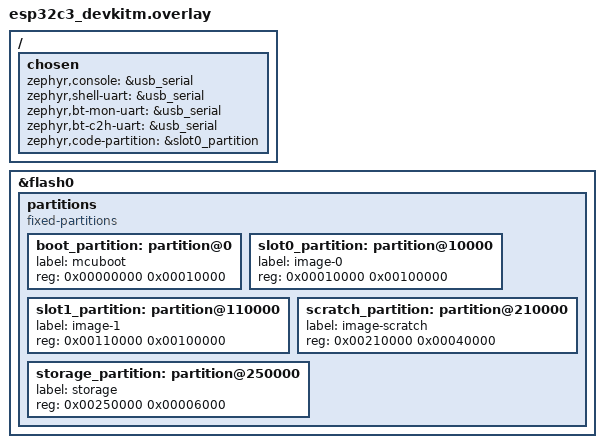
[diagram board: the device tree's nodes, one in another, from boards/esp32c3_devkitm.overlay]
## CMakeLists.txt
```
cmake_minimum_required(VERSION 3.20.0)

find_package(Zephyr REQUIRED HINTS $ENV{ZEPHYR_BASE})
project(ots_ota_app)

target_sources(app PRIVATE src/main.c src/ots_ota.c)
```

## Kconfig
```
mainmenu "OTS OTA Application"

source "Kconfig.zephyr"
```

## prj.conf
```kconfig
CONFIG_BT=y
CONFIG_BT_PERIPHERAL=y
CONFIG_BT_DEVICE_NAME="Zephyr OTS OTA"
CONFIG_BT_MAX_CONN=2
CONFIG_BT_MAX_PAIRED=1

# Object Transfer Service (OTS)
CONFIG_BT_OTS=y
CONFIG_BT_OTS_SECONDARY_SVC=y
CONFIG_BT_OTS_MAX_OBJ_CNT=5
# We need to support writing to objects
CONFIG_BT_OTS_OACP_WRITE_SUPPORT=y
CONFIG_BT_OTS_OACP_CREATE_SUPPORT=y
# Required for OACP Create support
CONFIG_BT_OTS_OBJ_NAME_WRITE_SUPPORT=y

# L2CAP Tuning for OTS
CONFIG_BT_L2CAP_DYNAMIC_CHANNEL=y
CONFIG_BT_L2CAP_TX_BUF_COUNT=15
CONFIG_BT_BUF_ACL_TX_COUNT=15
CONFIG_BT_BUF_EVT_RX_COUNT=16
CONFIG_BT_BUF_ACL_RX_SIZE=251
CONFIG_BT_BUF_ACL_TX_SIZE=251
CONFIG_BT_L2CAP_TX_MTU=247

# OLCP Features
CONFIG_BT_OTS_OLCP_GO_TO_SUPPORT=y

# Flash and OTA dependencies
# Flash and OTA dependencies
CONFIG_FLASH=y
CONFIG_FLASH_MAP=y
CONFIG_STREAM_FLASH=y
CONFIG_IMG_MANAGER=y
CONFIG_MCUBOOT_IMG_MANAGER=y
CONFIG_STREAM_FLASH_ERASE=y

# Bootloader integration
CONFIG_BOOTLOADER_MCUBOOT=y

# main stack
CONFIG_MAIN_STACK_SIZE=4096
CONFIG_SYSTEM_WORKQUEUE_STACK_SIZE=2048

# Logging & Console
CONFIG_LOG=y
CONFIG_LOG_MODE_DEFERRED=y
CONFIG_CONSOLE=y
CONFIG_UART_CONSOLE=y
CONFIG_STDOUT_CONSOLE=y
CONFIG_PRINTK=y
CONFIG_SERIAL=y
CONFIG_UART_INTERRUPT_DRIVEN=y
CONFIG_BT_OTS_LOG_LEVEL_DBG=y
CONFIG_BT_L2CAP_LOG_LEVEL_INF=y
CONFIG_STREAM_FLASH_LOG_LEVEL_INF=y

# Bluetooth Link Tuning
CONFIG_BT_PERIPHERAL_PREF_TIMEOUT=400
CONFIG_BT_PERIPHERAL_PREF_MIN_INT=16
CONFIG_BT_PERIPHERAL_PREF_MAX_INT=24

# Hardware info
CONFIG_GPIO=y
CONFIG_REBOOT=y
```

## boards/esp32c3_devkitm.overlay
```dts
/ {
	chosen {
		zephyr,console = &usb_serial;
		zephyr,shell-uart = &usb_serial;
		zephyr,bt-mon-uart = &usb_serial;
		zephyr,bt-c2h-uart = &usb_serial;
		zephyr,code-partition = &slot0_partition;
	};
};

&flash0 {
	/delete-node/ partitions;

	partitions {
		compatible = "fixed-partitions";
		#address-cells = <1>;
		#size-cells = <1>;

		boot_partition: partition@0 {
			label = "mcuboot";
			reg = <0x00000000 0x00010000>;
		};

		slot0_partition: partition@10000 {
			label = "image-0";
			reg = <0x00010000 0x00100000>;
		};

		slot1_partition: partition@110000 {
			label = "image-1";
			reg = <0x00110000 0x00100000>;
		};

		scratch_partition: partition@210000 {
			label = "image-scratch";
			reg = <0x00210000 0x00040000>;
		};

		storage_partition: partition@250000 {
			label = "storage";
			reg = <0x00250000 0x00006000>;
		};
	};
};
```

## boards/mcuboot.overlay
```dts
&flash0 {
	/delete-node/ partitions;

	partitions {
		compatible = "fixed-partitions";
		#address-cells = <1>;
		#size-cells = <1>;

		boot_partition: partition@0 {
			label = "mcuboot";
			reg = <0x00000000 0x00010000>;
		};

		slot0_partition: partition@10000 {
			label = "image-0";
			reg = <0x00010000 0x00100000>;
		};

		slot1_partition: partition@110000 {
			label = "image-1";
			reg = <0x00110000 0x00100000>;
		};

		scratch_partition: partition@210000 {
			label = "image-scratch";
			reg = <0x00210000 0x00040000>;
		};

		storage_partition: partition@250000 {
			label = "storage";
			reg = <0x00250000 0x00006000>;
		};
	};
};
```

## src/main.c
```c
#include <zephyr/kernel.h>
#include <zephyr/bluetooth/bluetooth.h>
#include <zephyr/bluetooth/conn.h>
#include <zephyr/bluetooth/gatt.h>
#include <zephyr/bluetooth/services/ots.h>
#include <zephyr/storage/stream_flash.h>
#include <zephyr/storage/flash_map.h>
#include <zephyr/dfu/mcuboot.h>
#include <zephyr/sys/reboot.h>
#include <zephyr/logging/log.h>
#include "ots_ota.h"

LOG_MODULE_REGISTER(main, CONFIG_BT_L2CAP_LOG_LEVEL);

#define DEVICE_NAME      CONFIG_BT_DEVICE_NAME
#define DEVICE_NAME_LEN  (sizeof(DEVICE_NAME) - 1)

static const struct bt_data ad[] = {
	BT_DATA_BYTES(BT_DATA_FLAGS, (BT_LE_AD_GENERAL | BT_LE_AD_NO_BREDR)),
    BT_DATA(BT_DATA_NAME_COMPLETE, DEVICE_NAME, DEVICE_NAME_LEN),
	BT_DATA_BYTES(BT_DATA_UUID16_ALL, BT_UUID_16_ENCODE(BT_UUID_OTS_VAL)),
};

static void connected(struct bt_conn *conn, uint8_t err)
{
	if (err) {
		LOG_ERR("Bluetooth: Connection failed (err 0x%02x)", err);
	} else {
		LOG_INF("Bluetooth: Connected");
	}
}

static void disconnected(struct bt_conn *conn, uint8_t reason)
{
	LOG_INF("Bluetooth: Disconnected (reason 0x%02x)", reason);
    
    // Restart advertising
    int err = bt_le_adv_start(BT_LE_ADV_CONN_FAST_1, ad, ARRAY_SIZE(ad), NULL, 0);
    if (err) {
        LOG_ERR("Bluetooth: Advertising failed to restart (err %d)", err);
    } else {
        LOG_INF("Bluetooth: Advertising restarted");
    }
}

BT_CONN_CB_DEFINE(conn_callbacks) = {
	.connected = connected,
	.disconnected = disconnected,
};

int main(void)
{
	int err;

	LOG_INF("*** Starting OTS OTA App v2.0.1 ***");

	err = bt_enable(NULL);
	if (err) {
		LOG_ERR("Bluetooth: Init failed (err %d)", err);
		return 0;
	}

    err = ots_ota_init();
    if (err) {
        LOG_ERR("OTS OTA Init failed (err %d)", err);
    }

	err = bt_le_adv_start(BT_LE_ADV_CONN_FAST_1, ad, ARRAY_SIZE(ad), NULL, 0);
	if (err) {
		LOG_ERR("Bluetooth: Advertising start failed (err %d)", err);
		return 0;
	}

	LOG_INF("Bluetooth: Advertising started");

	return 0;
}
```

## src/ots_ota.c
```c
#include <zephyr/kernel.h>
#include <zephyr/bluetooth/bluetooth.h>
#include <zephyr/bluetooth/conn.h>
#include <zephyr/bluetooth/services/ots.h>
#include <zephyr/storage/stream_flash.h>
#include <zephyr/storage/flash_map.h>
#include <zephyr/dfu/mcuboot.h>
#include <zephyr/sys/reboot.h>
#include <zephyr/logging/log.h>

#include "ots_ota.h"

LOG_MODULE_REGISTER(ots_ota, CONFIG_BT_OTS_LOG_LEVEL);

#define SLOT1_LABEL		slot1_partition
#define SLOT1_ID		FIXED_PARTITION_ID(SLOT1_LABEL)
#define SLOT1_DEV		FIXED_PARTITION_DEVICE(SLOT1_LABEL)
#define STREAM_FLASH_BUF_SIZE 1024

static struct stream_flash_ctx stream_ctx;
static uint8_t stream_flash_buf[STREAM_FLASH_BUF_SIZE];
static struct bt_ots *ots_instance;

static int ots_obj_created(struct bt_ots *ots, struct bt_conn *conn, uint64_t id,
			   const struct bt_ots_obj_add_param *param,
			   struct bt_ots_obj_created_desc *created_desc)
{
    static char firmware_name[] = "firmware.bin";

	LOG_INF("OTS Callback: Object Created ID 0x%llx, Size %u", id, param->size);

    created_desc->name = firmware_name;
    created_desc->size.alloc = param->size;
    created_desc->size.cur = 0;
    
    BT_OTS_OBJ_SET_PROP_WRITE(created_desc->props);
    BT_OTS_OBJ_SET_PROP_READ(created_desc->props);

	LOG_INF("OTS Callback: Object registered successfully. Ready for Write.");

	return 0;
}

static int ots_obj_write(struct bt_ots *ots, struct bt_conn *conn, uint64_t id,
			 const void *data, size_t len, off_t offset, size_t rem)
{
	int err;

	LOG_DBG("OTS Callback: Write Request. Offset %ld, Len %zu, Rem %zu", (long)offset, len, rem);

    if (offset == 0) {
        LOG_INF("OTS: Initializing Flash for new transfer...");
        
        if (!device_is_ready(SLOT1_DEV)) {
		    LOG_ERR("OTS: Error - Flash device not ready");
            return -ENODEV;
	    }

        err = stream_flash_init(&stream_ctx, SLOT1_DEV,
                    stream_flash_buf, sizeof(stream_flash_buf),
                    FIXED_PARTITION_OFFSET(SLOT1_LABEL),
                    FIXED_PARTITION_SIZE(SLOT1_LABEL),
                    NULL);
        if (err) {
            LOG_ERR("OTS: Error - Stream flash init failed (err %d)", err);
            return err;
        }
    }

	err = stream_flash_buffered_write(&stream_ctx, data, len, (rem == 0));
	if (err) {
		LOG_ERR("OTS: Error - Stream flash write failed (err %d)", err);
		return err;
	}

	if (rem == 0) {
		LOG_INF("OTS: Transfer complete! Finalizing...");
		
#ifdef CONFIG_BOOTLOADER_MCUBOOT
        err = boot_request_upgrade(BOOT_UPGRADE_TEST);
        if (err) {
            LOG_ERR("OTS: Error - Failed to request upgrade (err %d)", err);
        } else {
            LOG_INF("OTS: Upgrade requested. Rebooting...");
            k_sleep(K_SECONDS(2));
            sys_reboot(SYS_REBOOT_COLD);
        }
#else
        LOG_INF("OTS: MCUboot not enabled. Rebooting in 2s...");
        k_sleep(K_SECONDS(2));
        sys_reboot(SYS_REBOOT_COLD);
#endif
	}

	return len;
}

static struct bt_ots_cb ots_callbacks = {
	.obj_created = ots_obj_created,
	.obj_write = ots_obj_write,
};

int ots_ota_init(void)
{
	int err;

	ots_instance = bt_ots_free_instance_get();
	if (!ots_instance) {
		LOG_ERR("OTS: Error - Failed to retrieve OTS instance");
		return -ENOTCONN;
	}

    struct bt_ots_init_param ots_init = {0};
    
    BT_OTS_OACP_SET_FEAT_READ(ots_init.features.oacp);
    BT_OTS_OACP_SET_FEAT_WRITE(ots_init.features.oacp);
    BT_OTS_OACP_SET_FEAT_CREATE(ots_init.features.oacp);
    BT_OTS_OLCP_SET_FEAT_GO_TO(ots_init.features.olcp);
    
	ots_init.cb = &ots_callbacks;

    err = bt_ots_init(ots_instance, &ots_init);
    if (err) {
         LOG_ERR("OTS: Error - Failed to init OTS (err %d)", err);
         return err;
    }

    static struct bt_ots_obj_add_param add_param;
    add_param.size = FIXED_PARTITION_SIZE(SLOT1_LABEL);
    add_param.type.uuid.type = BT_UUID_TYPE_16;
    add_param.type.uuid_16.val = BT_UUID_OTS_TYPE_UNSPECIFIED_VAL;
    
    err = bt_ots_obj_add(ots_instance, &add_param);
    if (err < 0) {
        LOG_ERR("OTS: Error - Failed to add firmware object (err %d)", err);
        return err;
    }

    LOG_INF("OTS: Firmware object added (Max Size: %u)", add_param.size);

    return 0;
}
```

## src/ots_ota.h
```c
#ifndef OTS_OTA_H_
#define OTS_OTA_H_

/**
 * @brief Initialize the OTS OTA service.
 * 
 * @return int 0 on success, negative error code otherwise.
 */
int ots_ota_init(void);

#endif /* OTS_OTA_H_ */
```
